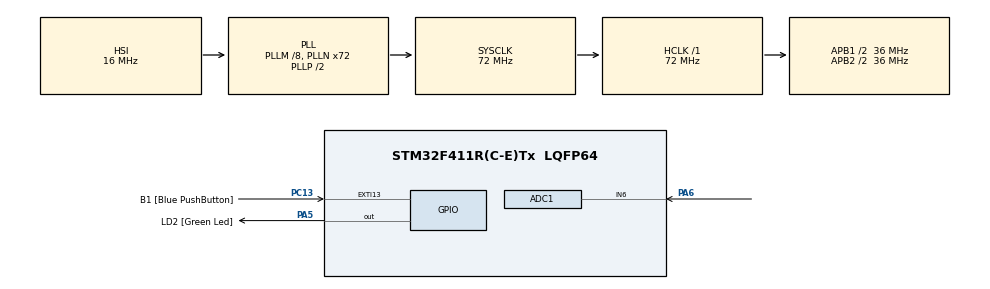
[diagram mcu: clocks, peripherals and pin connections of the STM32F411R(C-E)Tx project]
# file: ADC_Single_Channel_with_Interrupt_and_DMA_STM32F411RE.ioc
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ADC1.Channel-1\#ChannelRegularConversion=ADC_CHANNEL_6
ADC1.ClockPrescaler=ADC_CLOCK_SYNC_PCLK_DIV8
ADC1.ContinuousConvMode=ENABLE
ADC1.NbrOfConversion=1
ADC1.NbrOfConversionFlag=1
ADC1.Rank-1\#ChannelRegularConversion=1
ADC1.SamplingTime-1\#ChannelRegularConversion=ADC_SAMPLETIME_480CYCLES
ADC1.master=1
Mcu.Family=STM32F4
Mcu.Name=STM32F411R(C-E)Tx
Mcu.Package=LQFP64
NVIC.ADC_IRQn=true\:0\:0\:false\:false\:true\:true\:true\:true
NVIC.PriorityGroup=NVIC_PRIORITYGROUP_0
PA13.GPIO_Label=TMS
PA13.Mode=Serial_Wire
PA13.Signal=SYS_JTMS-SWDIO
PA14.GPIO_Label=TCK
PA14.Mode=Serial_Wire
PA14.Signal=SYS_JTCK-SWCLK
PA5.GPIO_Label=LD2 [Green Led]
PA5.Signal=GPIO_Output
PA6.Signal=ADCx_IN6
PB3.GPIO_Label=SWO
PB3.Signal=SYS_JTDO-SWO
PC13-ANTI_TAMP.GPIO_Label=B1 [Blue PushButton]
PC13-ANTI_TAMP.GPIO_ModeDefaultEXTI=GPIO_MODE_IT_FALLING
PC13-ANTI_TAMP.Signal=GPXTI13
PC14-OSC32_IN.Mode=LSE-External-Oscillator
PC14-OSC32_IN.Signal=RCC_OSC32_IN
PC15-OSC32_OUT.Mode=LSE-External-Oscillator
PC15-OSC32_OUT.Signal=RCC_OSC32_OUT
PH0\ -\ OSC_IN.Mode=HSE-External-Clock-Source
PH0\ -\ OSC_IN.Signal=RCC_OSC_IN
PH1\ -\ OSC_OUT.Mode=HSE-External-Clock-Source
PH1\ -\ OSC_OUT.Signal=RCC_OSC_OUT
ProjectManager.HeapSize=0x200
ProjectManager.StackSize=0x400
ProjectManager.TargetToolchain=STM32CubeIDE
RCC.48MHZClocksFreq_Value=36000000
RCC.AHBFreq_Value=72000000
RCC.APB1CLKDivider=RCC_HCLK_DIV2
RCC.APB1Freq_Value=36000000
RCC.APB1TimFreq_Value=72000000
RCC.APB2CLKDivider=RCC_HCLK_DIV2
RCC.APB2Freq_Value=36000000
RCC.APB2TimFreq_Value=72000000
RCC.CortexFreq_Value=72000000
RCC.FLatency-AdvancedSettings=FLASH_LATENCY_2
RCC.HCLKFreq_Value=72000000
RCC.HSE_VALUE=8000000
RCC.HSI_VALUE=16000000
RCC.PLLM=8
RCC.PLLN=72
RCC.SYSCLKFreq_VALUE=72000000
RCC.SYSCLKSource=RCC_SYSCLKSOURCE_PLLCLK
RCC.VCOOutputFreq_Value=144000000
SH.ADCx_IN6.0=ADC1_IN6,IN6
board=NUCLEO-F411RE

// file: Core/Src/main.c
/* USER CODE BEGIN Header */
/**
  ******************************************************************************
  * @file           : main.c
  * @brief          : Main program body
  ******************************************************************************
  * @attention
  *
  * Copyright (c) 2025 STMicroelectronics.
  * All rights reserved.
  *
  * This software is licensed under terms that can be found in the LICENSE file
  * in the root directory of this software component.
  * If no LICENSE file comes with this software, it is provided AS-IS.
  *
  ******************************************************************************
  */
/* USER CODE END Header */
#include "main.h"

ADC_HandleTypeDef hadc1;

/* USER CODE BEGIN PV */
volatile uint16_t ADC_VAL = 0;
volatile int value = 0;

/* USER CODE END PV */

void SystemClock_Config(void);
static void MX_GPIO_Init(void);
static void MX_ADC1_Init(void);

/* USER CODE BEGIN 0 */
long map(long x, long in_min, long in_max, long out_min, long out_max);
/* USER CODE END 0 */

int main(void)
{

  /* MCU Configuration--------------------------------------------------------*/

  /* Reset of all peripherals, Initializes the Flash interface and the Systick. */
  HAL_Init();

  /* Configure the system clock */
  SystemClock_Config();

  /* Initialize all configured peripherals */
  MX_GPIO_Init();
  MX_ADC1_Init();
  /* USER CODE BEGIN 2 */
  HAL_ADC_Start_IT(&hadc1);
  /* USER CODE END 2 */

  /* Infinite loop */
  /* USER CODE BEGIN WHILE */
  HAL_ADC_Start_DMA(&hadc1, (uint32_t *)ADC_VAL, 1);
  while (1)
  {
  }
  /* USER CODE END 3 */
}

void SystemClock_Config(void)
{
  RCC_OscInitTypeDef RCC_OscInitStruct = {0};
  RCC_ClkInitTypeDef RCC_ClkInitStruct = {0};

  /** Configure the main internal regulator output voltage
  */
  __HAL_RCC_PWR_CLK_ENABLE();
  __HAL_PWR_VOLTAGESCALING_CONFIG(PWR_REGULATOR_VOLTAGE_SCALE1);

  /** Initializes the RCC Oscillators according to the specified parameters
  * in the RCC_OscInitTypeDef structure.
  */
  RCC_OscInitStruct.OscillatorType = RCC_OSCILLATORTYPE_HSI;
  RCC_OscInitStruct.HSIState = RCC_HSI_ON;
  RCC_OscInitStruct.HSICalibrationValue = RCC_HSICALIBRATION_DEFAULT;
  RCC_OscInitStruct.PLL.PLLState = RCC_PLL_ON;
  RCC_OscInitStruct.PLL.PLLSource = RCC_PLLSOURCE_HSI;
  RCC_OscInitStruct.PLL.PLLM = 8;
  RCC_OscInitStruct.PLL.PLLN = 72;
  RCC_OscInitStruct.PLL.PLLP = RCC_PLLP_DIV2;
  RCC_OscInitStruct.PLL.PLLQ = 4;
  if (HAL_RCC_OscConfig(&RCC_OscInitStruct) != HAL_OK)
  {
    Error_Handler();
  }

  /** Initializes the CPU, AHB and APB buses clocks
  */
  RCC_ClkInitStruct.ClockType = RCC_CLOCKTYPE_HCLK|RCC_CLOCKTYPE_SYSCLK
                              |RCC_CLOCKTYPE_PCLK1|RCC_CLOCKTYPE_PCLK2;
  RCC_ClkInitStruct.SYSCLKSource = RCC_SYSCLKSOURCE_PLLCLK;
  RCC_ClkInitStruct.AHBCLKDivider = RCC_SYSCLK_DIV1;
  RCC_ClkInitStruct.APB1CLKDivider = RCC_HCLK_DIV2;
  RCC_ClkInitStruct.APB2CLKDivider = RCC_HCLK_DIV2;

  if (HAL_RCC_ClockConfig(&RCC_ClkInitStruct, FLASH_LATENCY_2) != HAL_OK)
  {
    Error_Handler();
  }
}

static void MX_ADC1_Init(void)
{

  ADC_ChannelConfTypeDef sConfig = {0};

  /** Configure the global features of the ADC (Clock, Resolution, Data Alignment and number of conversion)
  */
  hadc1.Instance = ADC1;
  hadc1.Init.ClockPrescaler = ADC_CLOCK_SYNC_PCLK_DIV8;
  hadc1.Init.Resolution = ADC_RESOLUTION_12B;
  hadc1.Init.ScanConvMode = DISABLE;
  hadc1.Init.ContinuousConvMode = ENABLE;
  hadc1.Init.DiscontinuousConvMode = DISABLE;
  hadc1.Init.ExternalTrigConvEdge = ADC_EXTERNALTRIGCONVEDGE_NONE;
  hadc1.Init.ExternalTrigConv = ADC_SOFTWARE_START;
  hadc1.Init.DataAlign = ADC_DATAALIGN_RIGHT;
  hadc1.Init.NbrOfConversion = 1;
  hadc1.Init.DMAContinuousRequests = DISABLE;
  hadc1.Init.EOCSelection = ADC_EOC_SINGLE_CONV;
  if (HAL_ADC_Init(&hadc1) != HAL_OK)
  {
    Error_Handler();
  }

  /** Configure for the selected ADC regular channel its corresponding rank in the sequencer and its sample time.
  */
  sConfig.Channel = ADC_CHANNEL_6;
  sConfig.Rank = 1;
  sConfig.SamplingTime = ADC_SAMPLETIME_480CYCLES;
  if (HAL_ADC_ConfigChannel(&hadc1, &sConfig) != HAL_OK)
  {
    Error_Handler();
  }

}

static void MX_GPIO_Init(void)
{
  GPIO_InitTypeDef GPIO_InitStruct = {0};

  /* GPIO Ports Clock Enable */
  __HAL_RCC_GPIOC_CLK_ENABLE();
  __HAL_RCC_GPIOH_CLK_ENABLE();
  __HAL_RCC_GPIOA_CLK_ENABLE();
  __HAL_RCC_GPIOB_CLK_ENABLE();

  /*Configure GPIO pin Output Level */
  HAL_GPIO_WritePin(LD2_GPIO_Port, LD2_Pin, GPIO_PIN_RESET);

  /*Configure GPIO pin : B1_Pin */
  GPIO_InitStruct.Pin = B1_Pin;
  GPIO_InitStruct.Mode = GPIO_MODE_IT_FALLING;
  GPIO_InitStruct.Pull = GPIO_NOPULL;
  HAL_GPIO_Init(B1_GPIO_Port, &GPIO_InitStruct);

  /*Configure GPIO pin : LD2_Pin */
  GPIO_InitStruct.Pin = LD2_Pin;
  GPIO_InitStruct.Mode = GPIO_MODE_OUTPUT_PP;
  GPIO_InitStruct.Pull = GPIO_NOPULL;
  GPIO_InitStruct.Speed = GPIO_SPEED_FREQ_LOW;
  HAL_GPIO_Init(LD2_GPIO_Port, &GPIO_InitStruct);

}

/* USER CODE BEGIN 4 */

long map(long x, long in_min, long in_max, long out_min, long out_max)
{
  return (x - in_min) * (out_max - out_min + 1) / (in_max - in_min + 1) + out_min;
}

/* USER CODE BEGIN 4 */
// ... (votre fonction map) ...

void HAL_ADC_ConvCpltCallback(ADC_HandleTypeDef *hadc)
{
	  ADC_VAL = HAL_ADC_GetValue(&hadc1);
	  value = map(ADC_VAL, 0, 4095, 0, 100);
}
/* USER CODE END 4 */

void Error_Handler(void)
{
  __disable_irq();
  while (1)
  {
  }
}
